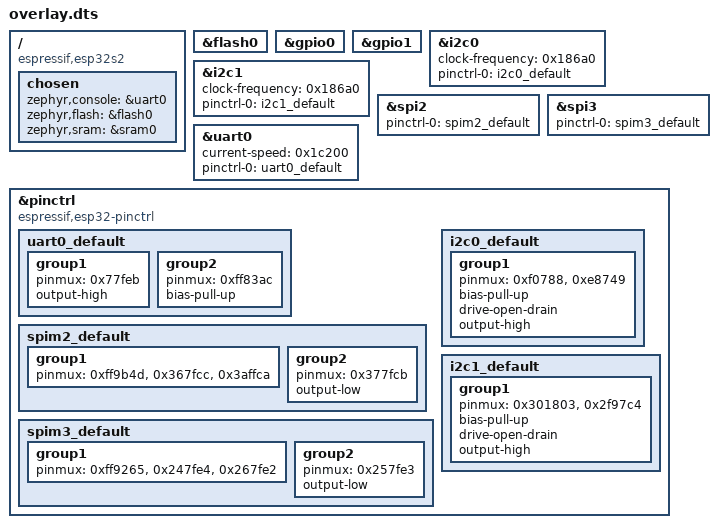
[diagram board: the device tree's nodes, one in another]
/ {
	compatible = "espressif,esp32s2";
	chosen {
		zephyr,console = &uart0;
		zephyr,flash = &flash0;
		zephyr,sram = &sram0;
	};
};
&flash0{
	status = "okay";
};
&gpio0{
	status = "okay";
};
&gpio1{
	status = "okay";
};
&i2c0{
	status = "okay";
	clock-frequency = < 0x186a0 >;
	pinctrl-0 = < &i2c0_default >;
	pinctrl-names = "default";
};
&i2c1{
	clock-frequency = < 0x186a0 >;
	pinctrl-0 = < &i2c1_default >;
	pinctrl-names = "default";
};
&spi2{
	status = "okay";
	#address-cells = < 0x1 >;
	#size-cells = < 0x0 >;
	pinctrl-0 = < &spim2_default >;
	pinctrl-names = "default";
};
&spi3{
	status = "okay";
	#address-cells = < 0x1 >;
	#size-cells = < 0x0 >;
	pinctrl-0 = < &spim3_default >;
	pinctrl-names = "default";
};
&uart0{
	status = "okay";
	current-speed = < 0x1c200 >;
	pinctrl-0 = < &uart0_default >;
	pinctrl-names = "default";
};
&pinctrl{
	compatible = "espressif,esp32-pinctrl";
	status = "okay";
	uart0_default: uart0_default {
		group1 {
			pinmux = < 0x77feb >;
			output-high;
		};
		group2 {
			pinmux = < 0xff83ac >;
			bias-pull-up;
		};
	};
	spim2_default: spim2_default {
		group1 {
			pinmux = < 0xff9b4d >, < 0x367fcc >, < 0x3affca >;
		};
		group2 {
			pinmux = < 0x377fcb >;
			output-low;
		};
	};
	spim3_default: spim3_default {
		group1 {
			pinmux = < 0xff9265 >, < 0x247fe4 >, < 0x267fe2 >;
		};
		group2 {
			pinmux = < 0x257fe3 >;
			output-low;
		};
	};
	i2c0_default: i2c0_default {
		group1 {
			pinmux = < 0xf0788 >, < 0xe8749 >;
			bias-pull-up;
			drive-open-drain;
			output-high;
		};
	};
	i2c1_default: i2c1_default {
		group1 {
			pinmux = < 0x301803 >, < 0x2f97c4 >;
			bias-pull-up;
			drive-open-drain;
			output-high;
		};
	};
};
